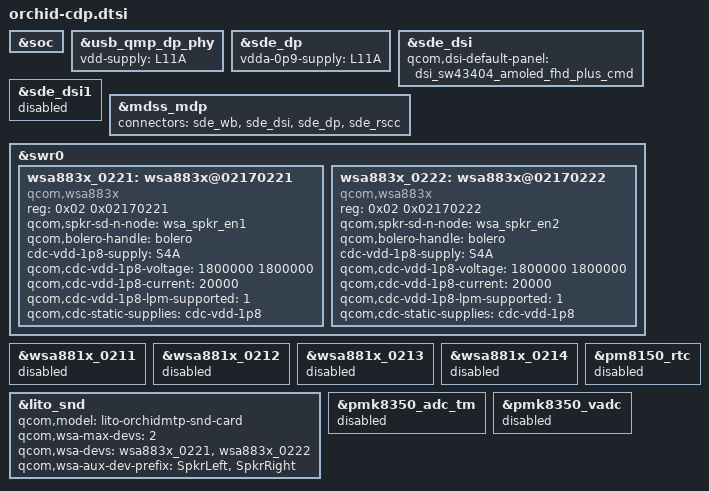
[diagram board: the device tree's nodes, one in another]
#include "lito-cdp.dtsi"

&soc {

};

&usb_qmp_dp_phy {
	/delete-property/vdd-supply;
	vdd-supply = <&L11A>;
};

&sde_dp {
	vdda-0p9-supply = <&L11A>;
};

&sde_dsi {
	qcom,dsi-default-panel = <&dsi_sw43404_amoled_fhd_plus_cmd>;
};

&sde_dsi1 {
	status = "disabled";
};

&mdss_mdp {
	connectors = <&sde_wb &sde_dsi &sde_dp &sde_rscc>;
};

&swr0 {
	wsa883x_0221: wsa883x@02170221 {
		compatible = "qcom,wsa883x";
		reg = <0x02 0x02170221>;
		qcom,spkr-sd-n-node = <&wsa_spkr_en1>;
		qcom,bolero-handle = <&bolero>;

		cdc-vdd-1p8-supply = <&S4A>;
		qcom,cdc-vdd-1p8-voltage = <1800000 1800000>;
		qcom,cdc-vdd-1p8-current = <20000>;
		qcom,cdc-vdd-1p8-lpm-supported = <1>;
		qcom,cdc-static-supplies = "cdc-vdd-1p8";
	};

	wsa883x_0222: wsa883x@02170222 {
		compatible = "qcom,wsa883x";
		reg = <0x02 0x02170222>;
		qcom,spkr-sd-n-node = <&wsa_spkr_en2>;
		qcom,bolero-handle = <&bolero>;

		cdc-vdd-1p8-supply = <&S4A>;
		qcom,cdc-vdd-1p8-voltage = <1800000 1800000>;
		qcom,cdc-vdd-1p8-current = <20000>;
		qcom,cdc-vdd-1p8-lpm-supported = <1>;
		qcom,cdc-static-supplies = "cdc-vdd-1p8";
	};
};

&wsa881x_0211 {
	status = "disabled";
};

&wsa881x_0212 {
	status = "disabled";
};

&wsa881x_0213 {
	status = "disabled";
};

&wsa881x_0214 {
	status = "disabled";
};

&lito_snd {
	qcom,model = "lito-orchidmtp-snd-card";
	qcom,wsa-max-devs = <2>;
	qcom,wsa-devs = <&wsa883x_0221>, <&wsa883x_0222>;
	qcom,wsa-aux-dev-prefix = "SpkrLeft", "SpkrRight";
};

&pm8150_rtc {
	status = "disabled";
};

&pmk8350_adc_tm {
	status = "disabled";
};

&pmk8350_vadc {
	status = "disabled";
};
